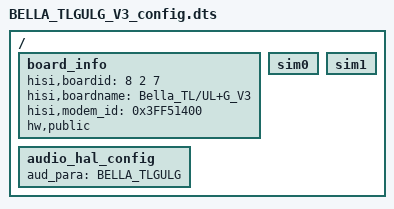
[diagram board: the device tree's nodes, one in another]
/*
 * Hisilicon Ltd.
 *
 * A15x4 A7x4
 *
 * It is only a demo for hisilicon hi3630 board. You show change the
 * address of each node according to datasheet.
 */

/dts-v1/;

/include/ "hisi_sim_hotplug.dtsi"

/include/ "BELLA_ULG_V3_config.dtsi"
/include/ "hisi_3630_pin_BELLA_TLGULG_V3.dtsi"
/include/ "hisi_3630_modem_BELLA_TLGULG_V3.dtsi"
/ {
	board_info: board_info {
		hisi,boardid = <8 2 7>;
		hisi,boardname = "Bella_TL/UL+G_V3";
		hisi,modem_id = <0x3FF51400>;
		hw,public;
	};
	sim0 {
		status = "ok";
	};
	sim1 {
		status = "ok";
	};
	audio_hal_config {
		aud_para = "BELLA_TLGULG";
	};
};
